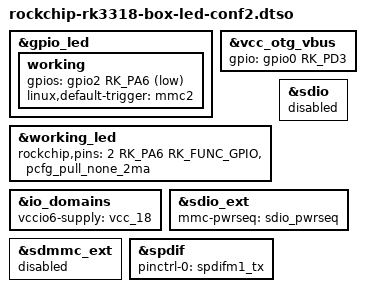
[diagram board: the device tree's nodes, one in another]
/dts-v1/;
/plugin/;

#include <dt-bindings/gpio/gpio.h>
#include <dt-bindings/input/input.h>
#include <dt-bindings/pinctrl/rockchip.h>


&gpio_led {

	working {
		gpios = <&gpio2 RK_PA6 GPIO_ACTIVE_LOW>;
		linux,default-trigger = "mmc2";
	};

	/*
	 * no auxiliary led on X88_PRO_B boards
	 *
	auxiliary {
		gpios = <&gpio0 RK_PA1 GPIO_ACTIVE_HIGH>;
		label = "auxiliary";
		linux,default-trigger = "mmc2";
		default-state = "off";
		pinctrl-names = "default";
		pinctrl-0 = <&gpio_led_aux>;
	};
	*/

};

&vcc_otg_vbus {
	gpio = <&gpio0 RK_PD3 GPIO_ACTIVE_HIGH>;
};

&working_led {
	rockchip,pins = <2 RK_PA6 RK_FUNC_GPIO &pcfg_pull_none_2ma>;
};

&io_domains {
	vccio6-supply = <&vcc_18>;
};

/*
 * Following section enables the sdio bus on sdmmc_ext controller
 */
&sdio {
	/delete-property/ mmc-pwrseq;
	status = "disabled";
};

&sdio_ext {
	mmc-pwrseq = <&sdio_pwrseq>;
	status = "okay";
};

&sdmmc_ext {
	status = "disabled";
};

&spdif {
	pinctrl-0 = <&spdifm1_tx>;
};

